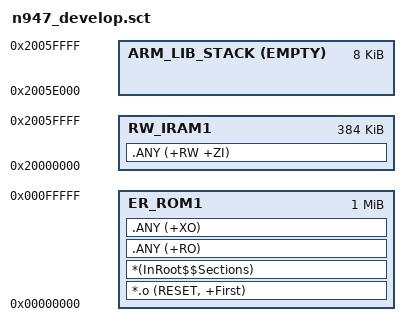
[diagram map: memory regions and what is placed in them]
; *************************************************************
; *** User-Defined Scatter-Loading Description File ***
; *************************************************************

LR_ROM1 0x00000000 0x00100000  {
  ER_ROM1 0x00000000 0x00100000  {  ; load address = execution address
   *.o (RESET, +First)
   *(InRoot$$Sections)
   .ANY (+RO)
   .ANY (+XO)
  }
  RW_IRAM1 0x20000000 0x00060000  {  ; RW data
   .ANY (+RW +ZI)
  }
  
  ARM_LIB_STACK 0x20060000 EMPTY -0x2000{  ; Stack region growing down
  
  }
}
